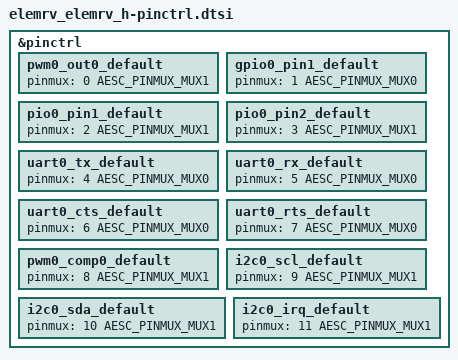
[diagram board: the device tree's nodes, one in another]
/*
 * Copyright (c) 2026 Aesc Silicon
 *
 * SPDX-License-Identifier: Apache-2.0
 */

#include <zephyr/dt-bindings/pinctrl/aesc-pinctrl.h>

&pinctrl {
	pwm0_out0_default: pwm0_out0_default {
		pinmux = <0 AESC_PINMUX_MUX1>;
	};

	gpio0_pin1_default: gpio0_pin1_default {
		pinmux = <1 AESC_PINMUX_MUX0>;
	};

	pio0_pin1_default: pio0_pin1_default {
		pinmux = <2 AESC_PINMUX_MUX1>;
	};

	pio0_pin2_default: pio0_pin2_default {
		pinmux = <3 AESC_PINMUX_MUX1>;
	};

	uart0_tx_default: uart0_tx_default {
		pinmux = <4 AESC_PINMUX_MUX0>;
	};

	uart0_rx_default: uart0_rx_default {
		pinmux = <5 AESC_PINMUX_MUX0>;
	};

	uart0_cts_default: uart0_cts_default {
		pinmux = <6 AESC_PINMUX_MUX0>;
	};

	uart0_rts_default: uart0_rts_default {
		pinmux = <7 AESC_PINMUX_MUX0>;
	};

	pwm0_comp0_default: pwm0_comp0_default {
		pinmux = <8 AESC_PINMUX_MUX1>;
	};

	i2c0_scl_default: i2c0_scl_default {
		pinmux = <9 AESC_PINMUX_MUX1>;
	};

	i2c0_sda_default: i2c0_sda_default {
		pinmux = <10 AESC_PINMUX_MUX1>;
	};

	i2c0_irq_default: i2c0_irq_default {
		pinmux = <11 AESC_PINMUX_MUX1>;
	};
};
